# ATmega2560 register map
Vendor: Atmel; File version: 1.0
CPU: other r0p0, little endian, no MPU, no FPU, 4 interrupt priority bits
Registers are 8-bit, read-write, reset 0x0 unless marked. A register's access mark holds for its fields unless they carry their own. Offsets are from the block's base; [hi:lo] are bit positions; {n}, {i} and the like mark numbered series; 'fields as' and 'values as' point back to an identical list.

## PORTL — I/O Port
Base 0x00000109
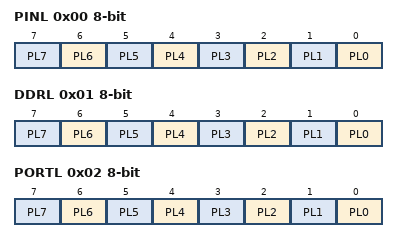
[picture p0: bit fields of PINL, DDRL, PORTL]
0x00 PINL — PORT L Input Pins
  [n] PL{n} (n=0..7) — Pin L{n}
0x01 DDRL — PORT L Data Direction Register
  [n] PL{n} (n=0..7) — Pin L{n}
0x02 PORTL — PORT L Data Register
  [n] PL{n} (n=0..7) — Pin L{n}

## SPI — Serial Peripheral Interface
Base 0x0000004C
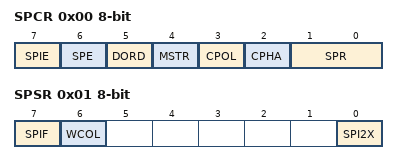
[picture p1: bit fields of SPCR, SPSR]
0x00 SPCR — SPI Control Register
  [7] SPIE — SPI Interrupt Enable
  [6] SPE — SPI Enable
  [5] DORD — Data Order
  [4] MSTR — Master/Slave Select
  [3] CPOL — Clock polarity
  [2] CPHA — Clock Phase
  [1:0] SPR — SPI Clock Rate Selects
    0=FOSC_4_2 (Fosc/4 if SPI2X == 0 else Fosc/2); 1=FOSC_16_8 (Fosc/16 if SPI2X == 0 else Fosc/8); 2=FOSC_64_32 (Fosc/64 if SPI2X == 0 else Fosc/32); 3=FOSC_128_64 (Fosc/128 if SPI2X == 0 else Fosc/64)
0x01 SPSR — SPI Status Register
  [7] SPIF ro — SPI Interrupt Flag
  [6] WCOL ro — Write Collision Flag
  [0] SPI2X — Double SPI Speed Bit
0x02 SPDR — SPI Data Register

## TC0 — Timer/Counter, 8-bit
Base 0x00000035
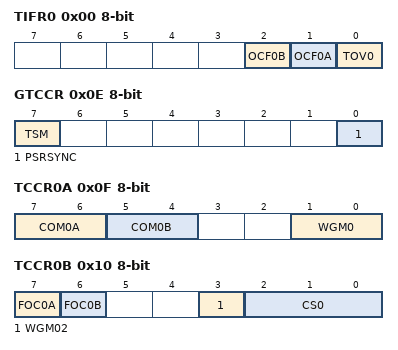
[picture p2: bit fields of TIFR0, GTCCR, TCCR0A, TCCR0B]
0x00 TIFR0 — Timer/Counter0 Interrupt Flag register
  [2] OCF0B — Timer/Counter0 Output Compare Flag 0B
  [1] OCF0A — Timer/Counter0 Output Compare Flag 0A
  [0] TOV0 — Timer/Counter0 Overflow Flag
0x0E GTCCR — General Timer/Counter Control Register
  [7] TSM — Timer/Counter Synchronization Mode
  [0] PSRSYNC — Prescaler Reset Timer/Counter1 and Timer/Counter0
0x0F TCCR0A — Timer/Counter Control Register A
  [7:6] COM0A — Compare Output A Mode
    0=DISCONNECTED (Normal port operation, OCix disconnected); 1=MATCH_TOGGLE (Toggle OCix on Compare Match (Might depend on WGM)); 2=MATCH_CLEAR (Clear OCix on Compare Match (If PWM is enabled, OCix is set at TOP)); 3=MATCH_SET (Set OCix on Compare Match (If PWM is enabled, OCix is cleared at TOP))
  [5:4] COM0B — Compare Output B Mode
    values as COM0A
  [1:0] WGM0 — Waveform Generation Mode
    0=NORMAL_TOP (Normal, Top: `0xff`, Update: *Immediate*, Flag: *MAX*); 1=PWM_PHASE (Phase Correct PWM, Top: `0xff`, Update: *TOP*, Flag: *BOTTOM*); 2=CTC (CTC, Top: *OCRA*, Update: *Immediate*, Flag: *MAX*); 3=PWM_FAST (Fast PWM, Top: `0xff`, Update: *TOP*, Flag: *MAX*)
0x10 TCCR0B — Timer/Counter Control Register B
  [7] FOC0A wo — Force Output Compare A
  [6] FOC0B wo — Force Output Compare B
  [3] WGM02 — Waveform Generation Mode High Bit (Enable Top: *OCRA* for `PWM` modes)
  [2:0] CS0 — Clock Select
    0=NO_CLOCK (No clock source (Timer/Counter stopped)); 1=DIRECT (Running, No Prescaling); 2=PRESCALE_8 (Running, CLK/8); 3=PRESCALE_64 (Running, CLK/64); 4=PRESCALE_256 (Running, CLK/256); 5=PRESCALE_1024 (Running, CLK/1024); 6=EXT_FALLING (Running, ExtClk Tx Falling Edge); 7=EXT_RISING (Running, ExtClk Tx Rising Edge)
0x11 TCNT0 — Timer/Counter0
0x12 OCR0A — Timer/Counter0 Output Compare Register
0x13 OCR0B — Timer/Counter0 Output Compare Register
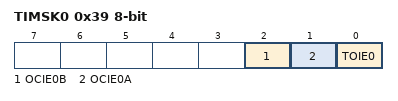
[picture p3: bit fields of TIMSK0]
0x39 TIMSK0 — Timer/Counter0 Interrupt Mask Register
  [2] OCIE0B — Timer/Counter0 Output Compare Match B Interrupt Enable
  [1] OCIE0A — Timer/Counter0 Output Compare Match A Interrupt Enable
  [0] TOIE0 — Timer/Counter0 Overflow Interrupt Enable

## TC1 — Timer/Counter, 16-bit
Base 0x00000036
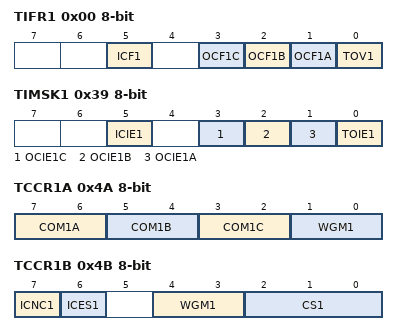
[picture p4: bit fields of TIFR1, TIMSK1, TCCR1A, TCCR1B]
0x00 TIFR1 — Timer/Counter1 Interrupt Flag register
  [5] ICF1 — Input Capture Flag 1
  [3] OCF1C — Output Compare Flag 1C
  [2] OCF1B — Output Compare Flag 1B
  [1] OCF1A — Output Compare Flag 1A
  [0] TOV1 — Timer/Counter1 Overflow Flag
0x39 TIMSK1 — Timer/Counter1 Interrupt Mask Register
  [5] ICIE1 — Timer/Counter1 Input Capture Interrupt Enable
  [3] OCIE1C — Timer/Counter1 Output Compare C Match Interrupt Enable
  [2] OCIE1B — Timer/Counter1 Output Compare B Match Interrupt Enable
  [1] OCIE1A — Timer/Counter1 Output Compare A Match Interrupt Enable
  [0] TOIE1 — Timer/Counter1 Overflow Interrupt Enable
0x4A TCCR1A — Timer/Counter1 Control Register A
  [7:6] COM1A — Compare Output Mode 1A, bits
    0=DISCONNECTED (Normal port operation, OCix disconnected); 1=MATCH_TOGGLE (Toggle OCix on Compare Match (Might depend on WGM)); 2=MATCH_CLEAR (Clear OCix on Compare Match (If PWM is enabled, OCix is set at BOTTOM)); 3=MATCH_SET (Set OCix on Compare Match (If PWM is enabled, OCix is cleared at BOTTOM))
  [5:4] COM1B — Compare Output Mode 1B, bits
    values as COM1A
  [3:2] COM1C — Compare Output Mode 1C, bits
    values as COM1A
  [1:0] WGM1 — Waveform Generation Mode
0x4B TCCR1B — Timer/Counter1 Control Register B
  [7] ICNC1 — Input Capture 1 Noise Canceler
  [6] ICES1 — Input Capture 1 Edge Select
  [4:3] WGM1 — Waveform Generation Mode
  [2:0] CS1 — Prescaler source of Timer/Counter 1
    0=NO_CLOCK (No clock source (Timer/Counter stopped)); 1=DIRECT (Running, No Prescaling); 2=PRESCALE_8 (Running, CLK/8); 3=PRESCALE_64 (Running, CLK/64); 4=PRESCALE_256 (Running, CLK/256); 5=PRESCALE_1024 (Running, CLK/1024); 6=EXT_FALLING (Running, ExtClk Tx Falling Edge); 7=EXT_RISING (Running, ExtClk Tx Rising Edge)
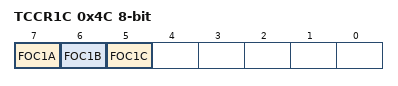
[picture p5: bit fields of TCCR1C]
0x4C TCCR1C — Timer/Counter 1 Control Register C
  [7] FOC1A wo — Force Output Compare 1A
  [6] FOC1B wo — Force Output Compare 1B
  [5] FOC1C wo — Force Output Compare 1C
0x4E TCNT1 16-bit (reset mask 0xFF) — Timer/Counter1 Bytes
0x50 ICR1 16-bit (reset mask 0xFF) — Timer/Counter1 Input Capture Register Bytes
0x52 OCR1A 16-bit (reset mask 0xFF) — Timer/Counter1 Output Compare Register A Bytes
0x54 OCR1B 16-bit (reset mask 0xFF) — Timer/Counter1 Output Compare Register B Bytes
0x56 OCR1C 16-bit (reset mask 0xFF) — Timer/Counter1 Output Compare Register C Bytes
